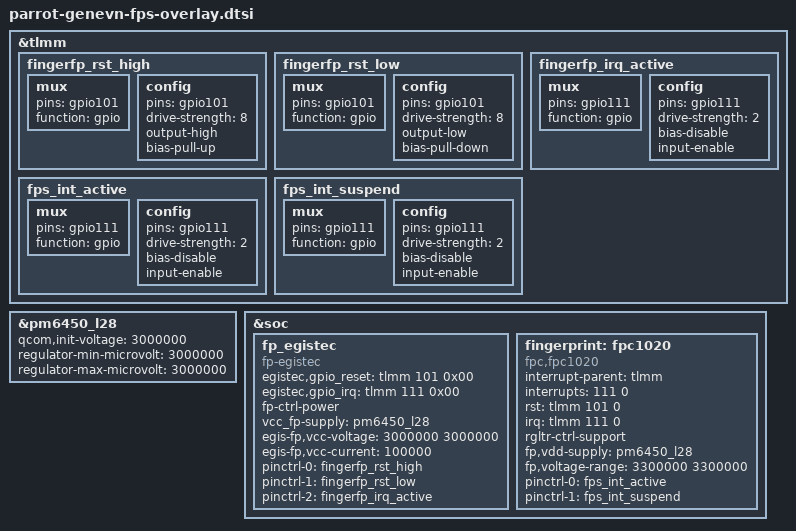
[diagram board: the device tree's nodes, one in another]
&tlmm {
	fingerfp_rst_high: fingerfp_rst_high {
		mux {
			pins = "gpio101";
			function = "gpio";
		};

		config {
			pins = "gpio101";
			drive-strength = <8>;
			output-high;
			bias-pull-up;
		};
	};

	fingerfp_rst_low: fingerfp_rst_low {
		mux {
			pins = "gpio101";
			function = "gpio";
		};
		config {
			pins = "gpio101";
			drive-strength = <8>;
			output-low;
			bias-pull-down;
		};
	};

	fingerfp_irq_active: fingerfp_irq_active {
		mux {
			pins = "gpio111";
			function = "gpio";
		};
		config {
			pins = "gpio111";
			drive-strength = <2>;
			bias-disable;
			input-enable;
		};
	};

	fps_int_active: fps_int_active {
		/* active state */
		mux {
			pins = "gpio111";
			function = "gpio";
		};

		config {
			pins = "gpio111";
			drive-strength = <2>; /* 2 MA */
			bias-disable;
			input-enable;
		};
	};

	fps_int_suspend: fps_int_suspend {
		/* sleep state */
		mux {
			pins = "gpio111";
			function = "gpio";
		};

		config {
			pins = "gpio111";
			drive-strength = <2>; /* 2 MA */
			bias-disable;
			input-enable;
		};
	};
};

&pm6450_l28 {
	qcom,init-voltage = <3000000>;
	regulator-min-microvolt = <3000000>;
	regulator-max-microvolt = <3000000>;
	status = "ok";
	//regulator-always-on;
};

&soc {

	fp_egistec {
		status = "ok";
		compatible = "fp-egistec";
		egistec,gpio_reset = <&tlmm 101 0x00>;
		egistec,gpio_irq = <&tlmm 111 0x00>;

		fp-ctrl-power;
		vcc_fp-supply = <&pm6450_l28>;
		egis-fp,vcc-voltage = <3000000 3000000>;
		egis-fp,vcc-current = <100000>;
		pinctrl-names = "egis_rst_high", "egis_rst_low", "egis_irq_active";
		pinctrl-0 = <&fingerfp_rst_high>;
		pinctrl-1 = <&fingerfp_rst_low>;
		pinctrl-2 = <&fingerfp_irq_active>;
	};

	fingerprint: fpc1020 {
                status = "ok";
		compatible = "fpc,fpc1020";
		interrupt-parent = <&tlmm>;
		interrupts = <111 0>;
		rst = <&tlmm 101 0>;
		irq = <&tlmm 111 0>;
		rgltr-ctrl-support;
		fp,vdd-supply=<&pm6450_l28>;
		fp,voltage-range = <3300000 3300000>;
		pinctrl-names = "default", "suspend";
		pinctrl-0 = <&fps_int_active>;
		pinctrl-1 = < &fps_int_suspend>;
	};
};
